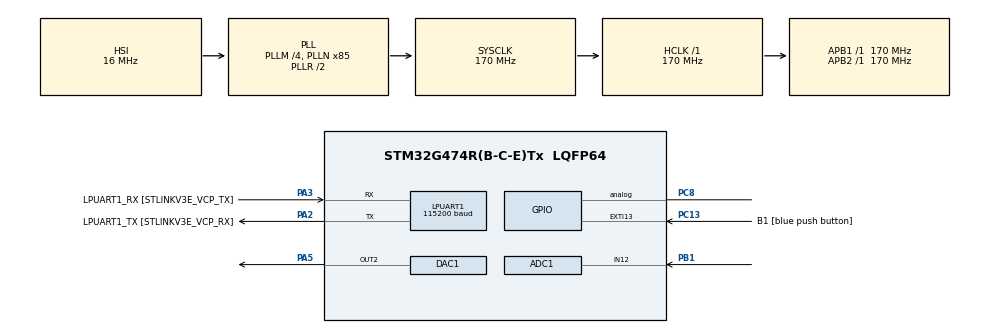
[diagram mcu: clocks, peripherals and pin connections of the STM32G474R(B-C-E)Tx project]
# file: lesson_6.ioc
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ADC1.Channel-0\#ChannelRegularConversion=ADC_CHANNEL_12
ADC1.ExternalTrigConv=ADC_EXTERNALTRIG_T1_TRGO
ADC1.NbrOfConversionFlag=1
ADC1.OffsetNumber-0\#ChannelRegularConversion=ADC_OFFSET_NONE
ADC1.Rank-0\#ChannelRegularConversion=1
ADC1.SamplingTime-0\#ChannelRegularConversion=ADC_SAMPLETIME_2CYCLES_5
ADC1.master=1
DAC1.DAC_Channel-DAC_OUT2=DAC_CHANNEL_2
LPUART1.BaudRate=115200
LPUART1.WordLength=UART_WORDLENGTH_8B
Mcu.Family=STM32G4
Mcu.Name=STM32G474R(B-C-E)Tx
Mcu.Package=LQFP64
NVIC.ADC1_2_IRQn=true\:0\:0\:false\:false\:true\:true\:true
NVIC.EXTI15_10_IRQn=true\:0\:0\:false\:false\:true\:true\:true
NVIC.PriorityGroup=NVIC_PRIORITYGROUP_4
PA13.GPIO_Label=T_SWDIO
PA13.Mode=Serial_Wire
PA13.Signal=SYS_JTMS-SWDIO
PA14.GPIO_Label=T_SWCLK
PA14.Mode=Serial_Wire
PA14.Signal=SYS_JTCK-SWCLK
PA2.GPIO_Label=LPUART1_TX [STLINKV3E_VCP_RX]
PA2.Mode=Asynchronous
PA2.Signal=LPUART1_TX
PA3.GPIO_Label=LPUART1_RX [STLINKV3E_VCP_TX]
PA3.Mode=Asynchronous
PA3.Signal=LPUART1_RX
PA5.Signal=COMP_DAC12_group
PB1.Mode=IN12-Single-Ended
PB1.Signal=ADC1_IN12
PB3.GPIO_Label=T_SWO
PB3.Signal=SYS_JTDO-SWO
PC13.GPIO_Label=B1 [blue push button]
PC13.Signal=GPXTI13
PC14-OSC32_IN.Mode=LSE-External-Oscillator
PC14-OSC32_IN.Signal=RCC_OSC32_IN
PC15-OSC32_OUT.Mode=LSE-External-Oscillator
PC15-OSC32_OUT.Signal=RCC_OSC32_OUT
PC8.Signal=GPIO_Analog
PF0-OSC_IN.Mode=HSE-External-Oscillator
PF0-OSC_IN.Signal=RCC_OSC_IN
PF1-OSC_OUT.Mode=HSE-External-Oscillator
PF1-OSC_OUT.Signal=RCC_OSC_OUT
ProjectManager.HeapSize=0x200
ProjectManager.StackSize=0x400
ProjectManager.TargetToolchain=STM32CubeIDE
RCC.ADC12Freq_Value=170000000
RCC.ADC345Freq_Value=170000000
RCC.AHBFreq_Value=170000000
RCC.APB1Freq_Value=170000000
RCC.APB1TimFreq_Value=170000000
RCC.APB2Freq_Value=170000000
RCC.APB2TimFreq_Value=170000000
RCC.CortexFreq_Value=170000000
RCC.EXTERNAL_CLOCK_VALUE=12288000
RCC.HCLKFreq_Value=170000000
RCC.HSE_VALUE=24000000
RCC.HSI48_VALUE=48000000
RCC.HSI_VALUE=16000000
RCC.PLLM=RCC_PLLM_DIV4
RCC.PLLN=85
RCC.RTCClockSelection=RCC_RTCCLKSOURCE_LSE
RCC.SYSCLKFreq_VALUE=170000000
RCC.SYSCLKSource=RCC_SYSCLKSOURCE_PLLCLK
RCC.USBFreq_Value=170000000
RCC.VCOOutputFreq_Value=340000000
SH.COMP_DAC12_group.0=DAC1_OUT2,DAC_OUT2
TIM1.Channel-Output\ Compare1\ No\ Output=TIM_CHANNEL_1
TIM1.PeriodNoDither=10000-1
TIM1.Prescaler=17000-1
TIM1.TIM_MasterOutputTrigger=TIM_TRGO_UPDATE
VP_SYS_VS_DBSignals.Mode=DisableDeadBatterySignals
VP_TIM1_VS_ClockSourceINT.Mode=Internal
VP_TIM1_VS_no_output1.Mode=Output Compare1 No Output
board=NUCLEO-G474RE

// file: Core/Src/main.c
/* USER CODE BEGIN Header */
/**
  ******************************************************************************
  * @file           : main.c
  * @brief          : Main program body
  ******************************************************************************
  * @attention
  *
  * Copyright (c) 2022 STMicroelectronics.
  * All rights reserved.
  *
  * This software is licensed under terms that can be found in the LICENSE file
  * in the root directory of this software component.
  * If no LICENSE file comes with this software, it is provided AS-IS.
  *
  ******************************************************************************
  */
/* USER CODE END Header */
#include "main.h"

ADC_HandleTypeDef hadc1;

DAC_HandleTypeDef hdac1;

UART_HandleTypeDef hlpuart1;

TIM_HandleTypeDef htim1;

/* USER CODE BEGIN PV */
int result;
/* USER CODE END PV */

void SystemClock_Config(void);
static void MX_GPIO_Init(void);
static void MX_LPUART1_UART_Init(void);
static void MX_ADC1_Init(void);
static void MX_TIM1_Init(void);
static void MX_DAC1_Init(void);

int main(void)
{

  /* MCU Configuration--------------------------------------------------------*/

  /* Reset of all peripherals, Initializes the Flash interface and the Systick. */
  HAL_Init();

  /* Configure the system clock */
  SystemClock_Config();

  /* Initialize all configured peripherals */
  MX_GPIO_Init();
  MX_LPUART1_UART_Init();
  MX_ADC1_Init();
  MX_TIM1_Init();
  MX_DAC1_Init();
  /* USER CODE BEGIN 2 */
  HAL_ADCEx_Calibration_Start(&hadc1, ADC_SINGLE_ENDED);
  HAL_ADC_Start_IT(&hadc1);
  HAL_TIM_Base_Start(&htim1);
  HAL_DAC_Start(&hdac1,DAC_CHANNEL_2);
  uint32_t i=0;
  /* USER CODE END 2 */

  /* Infinite loop */
  /* USER CODE BEGIN WHILE */
  while (1)
  {
	  if (result > 3000 && i > 0) i--;
	  if (result < 2900 && i < 4095) i++;
	  HAL_DAC_SetValue(&hdac1, DAC_CHANNEL_2,DAC_ALIGN_12B_R, i);
	  HAL_Delay(1);

	  /* USER CODE END WHILE */

  }
}

void SystemClock_Config(void)
{
  RCC_OscInitTypeDef RCC_OscInitStruct = {0};
  RCC_ClkInitTypeDef RCC_ClkInitStruct = {0};

  /** Configure the main internal regulator output voltage
  */
  HAL_PWREx_ControlVoltageScaling(PWR_REGULATOR_VOLTAGE_SCALE1_BOOST);
  /** Initializes the RCC Oscillators according to the specified parameters
  * in the RCC_OscInitTypeDef structure.
  */
  RCC_OscInitStruct.OscillatorType = RCC_OSCILLATORTYPE_HSI;
  RCC_OscInitStruct.HSIState = RCC_HSI_ON;
  RCC_OscInitStruct.HSICalibrationValue = RCC_HSICALIBRATION_DEFAULT;
  RCC_OscInitStruct.PLL.PLLState = RCC_PLL_ON;
  RCC_OscInitStruct.PLL.PLLSource = RCC_PLLSOURCE_HSI;
  RCC_OscInitStruct.PLL.PLLM = RCC_PLLM_DIV4;
  RCC_OscInitStruct.PLL.PLLN = 85;
  RCC_OscInitStruct.PLL.PLLP = RCC_PLLP_DIV2;
  RCC_OscInitStruct.PLL.PLLQ = RCC_PLLQ_DIV2;
  RCC_OscInitStruct.PLL.PLLR = RCC_PLLR_DIV2;
  if (HAL_RCC_OscConfig(&RCC_OscInitStruct) != HAL_OK)
  {
    Error_Handler();
  }
  /** Initializes the CPU, AHB and APB buses clocks
  */
  RCC_ClkInitStruct.ClockType = RCC_CLOCKTYPE_HCLK|RCC_CLOCKTYPE_SYSCLK
                              |RCC_CLOCKTYPE_PCLK1|RCC_CLOCKTYPE_PCLK2;
  RCC_ClkInitStruct.SYSCLKSource = RCC_SYSCLKSOURCE_PLLCLK;
  RCC_ClkInitStruct.AHBCLKDivider = RCC_SYSCLK_DIV1;
  RCC_ClkInitStruct.APB1CLKDivider = RCC_HCLK_DIV1;
  RCC_ClkInitStruct.APB2CLKDivider = RCC_HCLK_DIV1;

  if (HAL_RCC_ClockConfig(&RCC_ClkInitStruct, FLASH_LATENCY_4) != HAL_OK)
  {
    Error_Handler();
  }
}

static void MX_ADC1_Init(void)
{

  ADC_MultiModeTypeDef multimode = {0};
  ADC_ChannelConfTypeDef sConfig = {0};

  /** Common config
  */
  hadc1.Instance = ADC1;
  hadc1.Init.ClockPrescaler = ADC_CLOCK_SYNC_PCLK_DIV4;
  hadc1.Init.Resolution = ADC_RESOLUTION_12B;
  hadc1.Init.DataAlign = ADC_DATAALIGN_RIGHT;
  hadc1.Init.GainCompensation = 0;
  hadc1.Init.ScanConvMode = ADC_SCAN_DISABLE;
  hadc1.Init.EOCSelection = ADC_EOC_SINGLE_CONV;
  hadc1.Init.LowPowerAutoWait = DISABLE;
  hadc1.Init.ContinuousConvMode = DISABLE;
  hadc1.Init.NbrOfConversion = 1;
  hadc1.Init.DiscontinuousConvMode = DISABLE;
  hadc1.Init.ExternalTrigConv = ADC_EXTERNALTRIG_T1_TRGO;
  hadc1.Init.ExternalTrigConvEdge = ADC_EXTERNALTRIGCONVEDGE_RISING;
  hadc1.Init.DMAContinuousRequests = DISABLE;
  hadc1.Init.Overrun = ADC_OVR_DATA_PRESERVED;
  hadc1.Init.OversamplingMode = DISABLE;
  if (HAL_ADC_Init(&hadc1) != HAL_OK)
  {
    Error_Handler();
  }
  /** Configure the ADC multi-mode
  */
  multimode.Mode = ADC_MODE_INDEPENDENT;
  if (HAL_ADCEx_MultiModeConfigChannel(&hadc1, &multimode) != HAL_OK)
  {
    Error_Handler();
  }
  /** Configure Regular Channel
  */
  sConfig.Channel = ADC_CHANNEL_12;
  sConfig.Rank = ADC_REGULAR_RANK_1;
  sConfig.SamplingTime = ADC_SAMPLETIME_2CYCLES_5;
  sConfig.SingleDiff = ADC_SINGLE_ENDED;
  sConfig.OffsetNumber = ADC_OFFSET_NONE;
  sConfig.Offset = 0;
  if (HAL_ADC_ConfigChannel(&hadc1, &sConfig) != HAL_OK)
  {
    Error_Handler();
  }

}

static void MX_DAC1_Init(void)
{

  DAC_ChannelConfTypeDef sConfig = {0};

  /** DAC Initialization
  */
  hdac1.Instance = DAC1;
  if (HAL_DAC_Init(&hdac1) != HAL_OK)
  {
    Error_Handler();
  }
  /** DAC channel OUT2 config
  */
  sConfig.DAC_HighFrequency = DAC_HIGH_FREQUENCY_INTERFACE_MODE_AUTOMATIC;
  sConfig.DAC_DMADoubleDataMode = DISABLE;
  sConfig.DAC_SignedFormat = DISABLE;
  sConfig.DAC_SampleAndHold = DAC_SAMPLEANDHOLD_DISABLE;
  sConfig.DAC_Trigger = DAC_TRIGGER_NONE;
  sConfig.DAC_Trigger2 = DAC_TRIGGER_NONE;
  sConfig.DAC_OutputBuffer = DAC_OUTPUTBUFFER_ENABLE;
  sConfig.DAC_ConnectOnChipPeripheral = DAC_CHIPCONNECT_EXTERNAL;
  sConfig.DAC_UserTrimming = DAC_TRIMMING_FACTORY;
  if (HAL_DAC_ConfigChannel(&hdac1, &sConfig, DAC_CHANNEL_2) != HAL_OK)
  {
    Error_Handler();
  }

}

static void MX_LPUART1_UART_Init(void)
{

  hlpuart1.Instance = LPUART1;
  hlpuart1.Init.BaudRate = 115200;
  hlpuart1.Init.WordLength = UART_WORDLENGTH_8B;
  hlpuart1.Init.StopBits = UART_STOPBITS_1;
  hlpuart1.Init.Parity = UART_PARITY_NONE;
  hlpuart1.Init.Mode = UART_MODE_TX_RX;
  hlpuart1.Init.HwFlowCtl = UART_HWCONTROL_NONE;
  hlpuart1.Init.OneBitSampling = UART_ONE_BIT_SAMPLE_DISABLE;
  hlpuart1.Init.ClockPrescaler = UART_PRESCALER_DIV1;
  hlpuart1.AdvancedInit.AdvFeatureInit = UART_ADVFEATURE_NO_INIT;
  if (HAL_UART_Init(&hlpuart1) != HAL_OK)
  {
    Error_Handler();
  }
  if (HAL_UARTEx_SetTxFifoThreshold(&hlpuart1, UART_TXFIFO_THRESHOLD_1_8) != HAL_OK)
  {
    Error_Handler();
  }
  if (HAL_UARTEx_SetRxFifoThreshold(&hlpuart1, UART_RXFIFO_THRESHOLD_1_8) != HAL_OK)
  {
    Error_Handler();
  }
  if (HAL_UARTEx_DisableFifoMode(&hlpuart1) != HAL_OK)
  {
    Error_Handler();
  }

}

static void MX_TIM1_Init(void)
{

  TIM_ClockConfigTypeDef sClockSourceConfig = {0};
  TIM_MasterConfigTypeDef sMasterConfig = {0};
  TIM_OC_InitTypeDef sConfigOC = {0};
  TIM_BreakDeadTimeConfigTypeDef sBreakDeadTimeConfig = {0};

  htim1.Instance = TIM1;
  htim1.Init.Prescaler = 17000-1;
  htim1.Init.CounterMode = TIM_COUNTERMODE_UP;
  htim1.Init.Period = 9999;
  htim1.Init.ClockDivision = TIM_CLOCKDIVISION_DIV1;
  htim1.Init.RepetitionCounter = 0;
  htim1.Init.AutoReloadPreload = TIM_AUTORELOAD_PRELOAD_DISABLE;
  if (HAL_TIM_Base_Init(&htim1) != HAL_OK)
  {
    Error_Handler();
  }
  sClockSourceConfig.ClockSource = TIM_CLOCKSOURCE_INTERNAL;
  if (HAL_TIM_ConfigClockSource(&htim1, &sClockSourceConfig) != HAL_OK)
  {
    Error_Handler();
  }
  if (HAL_TIM_OC_Init(&htim1) != HAL_OK)
  {
    Error_Handler();
  }
  sMasterConfig.MasterOutputTrigger = TIM_TRGO_UPDATE;
  sMasterConfig.MasterOutputTrigger2 = TIM_TRGO2_RESET;
  sMasterConfig.MasterSlaveMode = TIM_MASTERSLAVEMODE_DISABLE;
  if (HAL_TIMEx_MasterConfigSynchronization(&htim1, &sMasterConfig) != HAL_OK)
  {
    Error_Handler();
  }
  sConfigOC.OCMode = TIM_OCMODE_TIMING;
  sConfigOC.Pulse = 0;
  sConfigOC.OCPolarity = TIM_OCPOLARITY_HIGH;
  sConfigOC.OCNPolarity = TIM_OCNPOLARITY_HIGH;
  sConfigOC.OCFastMode = TIM_OCFAST_DISABLE;
  sConfigOC.OCIdleState = TIM_OCIDLESTATE_RESET;
  sConfigOC.OCNIdleState = TIM_OCNIDLESTATE_RESET;
  if (HAL_TIM_OC_ConfigChannel(&htim1, &sConfigOC, TIM_CHANNEL_1) != HAL_OK)
  {
    Error_Handler();
  }
  sBreakDeadTimeConfig.OffStateRunMode = TIM_OSSR_DISABLE;
  sBreakDeadTimeConfig.OffStateIDLEMode = TIM_OSSI_DISABLE;
  sBreakDeadTimeConfig.LockLevel = TIM_LOCKLEVEL_OFF;
  sBreakDeadTimeConfig.DeadTime = 0;
  sBreakDeadTimeConfig.BreakState = TIM_BREAK_DISABLE;
  sBreakDeadTimeConfig.BreakPolarity = TIM_BREAKPOLARITY_HIGH;
  sBreakDeadTimeConfig.BreakFilter = 0;
  sBreakDeadTimeConfig.BreakAFMode = TIM_BREAK_AFMODE_INPUT;
  sBreakDeadTimeConfig.Break2State = TIM_BREAK2_DISABLE;
  sBreakDeadTimeConfig.Break2Polarity = TIM_BREAK2POLARITY_HIGH;
  sBreakDeadTimeConfig.Break2Filter = 0;
  sBreakDeadTimeConfig.Break2AFMode = TIM_BREAK_AFMODE_INPUT;
  sBreakDeadTimeConfig.AutomaticOutput = TIM_AUTOMATICOUTPUT_DISABLE;
  if (HAL_TIMEx_ConfigBreakDeadTime(&htim1, &sBreakDeadTimeConfig) != HAL_OK)
  {
    Error_Handler();
  }

}

static void MX_GPIO_Init(void)
{
  GPIO_InitTypeDef GPIO_InitStruct = {0};

  /* GPIO Ports Clock Enable */
  __HAL_RCC_GPIOC_CLK_ENABLE();
  __HAL_RCC_GPIOF_CLK_ENABLE();
  __HAL_RCC_GPIOA_CLK_ENABLE();
  __HAL_RCC_GPIOB_CLK_ENABLE();

  /*Configure GPIO pin : B1_Pin */
  GPIO_InitStruct.Pin = B1_Pin;
  GPIO_InitStruct.Mode = GPIO_MODE_IT_RISING;
  GPIO_InitStruct.Pull = GPIO_NOPULL;
  HAL_GPIO_Init(B1_GPIO_Port, &GPIO_InitStruct);

  /*Configure GPIO pin : PC8 */
  GPIO_InitStruct.Pin = GPIO_PIN_8;
  GPIO_InitStruct.Mode = GPIO_MODE_ANALOG;
  GPIO_InitStruct.Pull = GPIO_NOPULL;
  HAL_GPIO_Init(GPIOC, &GPIO_InitStruct);

  /* EXTI interrupt init*/
  HAL_NVIC_SetPriority(EXTI15_10_IRQn, 0, 0);
  HAL_NVIC_EnableIRQ(EXTI15_10_IRQn);

}

/* USER CODE BEGIN 4 */
void HAL_ADC_ConvCpltCallback(ADC_HandleTypeDef* hadc)
{
	result = HAL_ADC_GetValue(hadc);

}
/* USER CODE END 4 */

void Error_Handler(void)
{
  __disable_irq();
  while (1)
  {
  }
}
